VERSION ""

NS_ :

BS_:

BU_: XXX

BO_ 1044 2_414_acceleration: 8 XXX
 SG_ 2_414_EngineRPM : 52|13@0+ (1,0) [0|7500] "rpm" XXX

BO_ 336 0_150_Speed: 8 XXX
 SG_ 0_150_VehicleSpeed : 28|12@0+ (1,0) [0|0] "mph" XXX

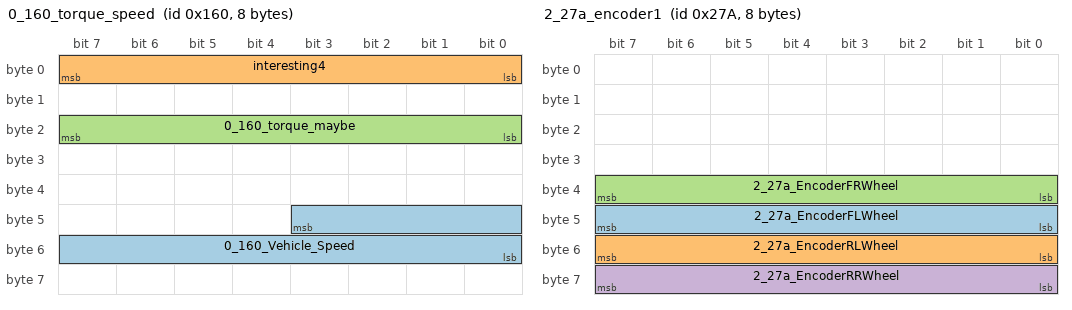
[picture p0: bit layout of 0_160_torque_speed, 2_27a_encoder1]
BO_ 352 0_160_torque_speed: 8 XXX
 SG_ 0_160_Vehicle_Speed : 43|12@0+ (1,0) [0|255] "" XXX
 SG_ interesting4 : 7|8@0+ (1,0) [0|8191] "" XXX
 SG_ 0_160_torque_maybe : 23|8@0+ (1,0) [0|255] "" XXX

BO_ 341 2_155_Suspension: 8 XXX
 SG_ 2_155_z_something : 23|8@0+ (1,0) [0|255] "" XXX

BO_ 634 2_27a_encoder1: 8 XXX
 SG_ 2_27a_EncoderFLWheel : 47|8@0+ (1,0) [0|255] "" XXX
 SG_ 2_27a_EncoderRLWheel : 55|8@0+ (1.411765,0) [0|255] "" XXX
 SG_ 2_27a_EncoderFRWheel : 39|8@0+ (1,0) [0|255] "" XXX
 SG_ 2_27a_EncoderRRWheel : 63|8@0+ (1,0) [0|255] "" XXX

BO_ 576 2_240_something: 8 XXX
 SG_ 2_240_something : 17|10@0+ (1,0) [0|255] "" XXX

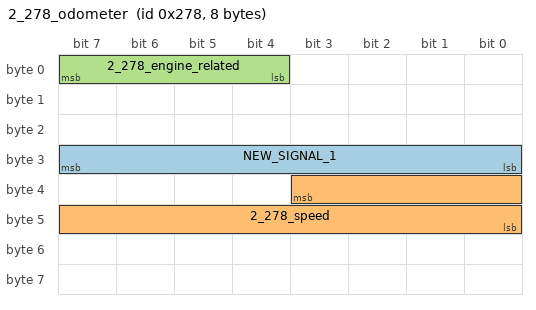
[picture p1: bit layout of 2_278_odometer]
BO_ 632 2_278_odometer: 8 XXX
 SG_ NEW_SIGNAL_1 : 31|8@0+ (1,0) [0|255] "" XXX
 SG_ 2_278_speed : 35|12@0+ (1,0) [0|255] "" XXX
 SG_ 2_278_engine_related : 7|4@0+ (1,0) [0|255] "" XXX

CM_ SG_ 336 0_150_VehicleSpeed "msb_certain_lsb_uncertain";
CM_ SG_ 632 2_278_engine_related "static_when_engine_stopped";
